# ATSAM3X8H device description
Architecture: CORTEX-M3; Family: SAM3; Series: SAM3XA
Registers are 32-bit, read-write, no defined reset value unless marked. A register's access mark holds for its fields unless they carry their own. Offsets are from the block's base; [hi:lo] are bit positions; {n}, {i} and the like mark numbered series.

## TRNG — True Random Number Generator
Instances: TRNG 0x400BC000
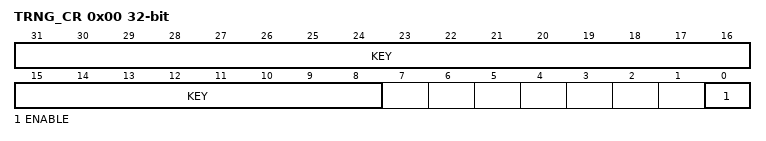
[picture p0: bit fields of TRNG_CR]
0x00 TRNG_CR wo — Control Register
  [31:8] KEY — Security Key
  [0] ENABLE — Enables the TRNG to provide random values
0x10 TRNG_IER wo — Interrupt Enable Register
  [0] DATRDY — Data Ready Interrupt Enable
0x14 TRNG_IDR wo — Interrupt Disable Register
  [0] DATRDY — Data Ready Interrupt Disable
0x18 TRNG_IMR ro — Interrupt Mask Register
  [0] DATRDY — Data Ready Interrupt Mask
0x1C TRNG_ISR ro — Interrupt Status Register
  [0] DATRDY — Data Ready
0x50 TRNG_ODATA ro — Output Data Register
  [31:0] ODATA — Output Data

## UART — Universal Asynchronous Receiver Transmitter
Instances: UART 0x400E0800
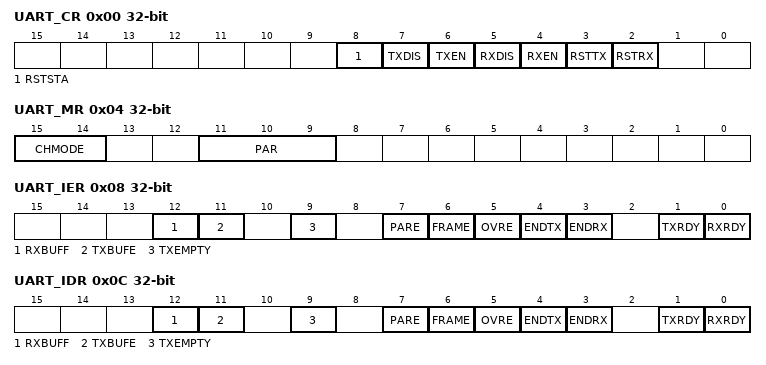
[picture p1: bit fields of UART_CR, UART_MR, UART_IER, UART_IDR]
0x00 UART_CR wo — Control Register
  [8] RSTSTA — Reset Status Bits
  [7] TXDIS — Transmitter Disable
  [6] TXEN — Transmitter Enable
  [5] RXDIS — Receiver Disable
  [4] RXEN — Receiver Enable
  [3] RSTTX — Reset Transmitter
  [2] RSTRX — Reset Receiver
0x04 UART_MR — Mode Register
  [15:14] CHMODE — Channel Mode
    0=NORMAL (Normal Mode); 1=AUTOMATIC (Automatic Echo); 2=LOCAL_LOOPBACK; 3=REMOTE_LOOPBACK
  [11:9] PAR — Parity Type
    0=EVEN (Even Parity); 1=ODD (Odd Parity); 2=SPACE (Space: parity forced to 0); 3=MARK (Mark: parity forced to 1); 4=NO (No Parity)
0x08 UART_IER wo — Interrupt Enable Register
  [12] RXBUFF — Enable Buffer Full Interrupt
  [11] TXBUFE — Enable Buffer Empty Interrupt
  [9] TXEMPTY — Enable TXEMPTY Interrupt
  [7] PARE — Enable Parity Error Interrupt
  [6] FRAME — Enable Framing Error Interrupt
  [5] OVRE — Enable Overrun Error Interrupt
  [4] ENDTX — Enable End of Transmit Interrupt
  [3] ENDRX — Enable End of Receive Transfer Interrupt
  [1] TXRDY — Enable TXRDY Interrupt
  [0] RXRDY — Enable RXRDY Interrupt
0x0C UART_IDR wo — Interrupt Disable Register
  [12] RXBUFF — Disable Buffer Full Interrupt
  [11] TXBUFE — Disable Buffer Empty Interrupt
  [9] TXEMPTY — Disable TXEMPTY Interrupt
  [7] PARE — Disable Parity Error Interrupt
  [6] FRAME — Disable Framing Error Interrupt
  [5] OVRE — Disable Overrun Error Interrupt
  [4] ENDTX — Disable End of Transmit Interrupt
  [3] ENDRX — Disable End of Receive Transfer Interrupt
  [1] TXRDY — Disable TXRDY Interrupt
  [0] RXRDY — Disable RXRDY Interrupt
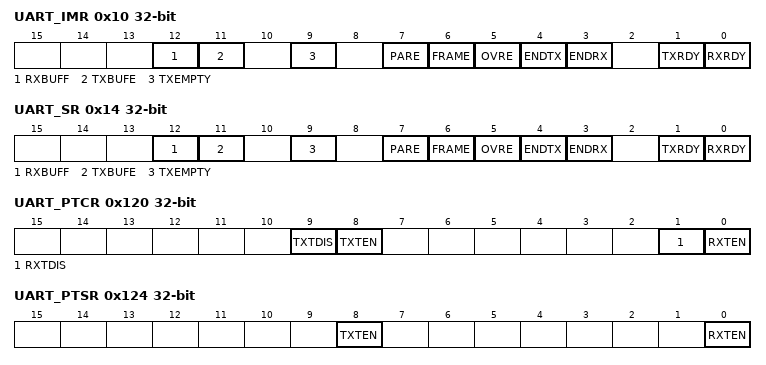
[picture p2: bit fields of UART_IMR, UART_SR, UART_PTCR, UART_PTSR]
0x10 UART_IMR ro — Interrupt Mask Register
  [12] RXBUFF — Mask RXBUFF Interrupt
  [11] TXBUFE — Mask TXBUFE Interrupt
  [9] TXEMPTY — Mask TXEMPTY Interrupt
  [7] PARE — Mask Parity Error Interrupt
  [6] FRAME — Mask Framing Error Interrupt
  [5] OVRE — Mask Overrun Error Interrupt
  [4] ENDTX — Mask End of Transmit Interrupt
  [3] ENDRX — Mask End of Receive Transfer Interrupt
  [1] TXRDY — Disable TXRDY Interrupt
  [0] RXRDY — Mask RXRDY Interrupt
0x14 UART_SR ro — Status Register
  [12] RXBUFF — Receive Buffer Full
  [11] TXBUFE — Transmission Buffer Empty
  [9] TXEMPTY — Transmitter Empty
  [7] PARE — Parity Error
  [6] FRAME — Framing Error
  [5] OVRE — Overrun Error
  [4] ENDTX — End of Transmitter Transfer
  [3] ENDRX — End of Receiver Transfer
  [1] TXRDY — Transmitter Ready
  [0] RXRDY — Receiver Ready
0x18 UART_RHR ro — Receive Holding Register
  [7:0] RXCHR — Received Character
0x1C UART_THR wo — Transmit Holding Register
  [7:0] TXCHR — Character to be Transmitted
0x20 UART_BRGR — Baud Rate Generator Register
  [15:0] CD — Clock Divisor
0x100 UART_RPR — Receive Pointer Register
  [31:0] RXPTR
0x104 UART_RCR — Receive Counter Register
  [15:0] RXCTR
0x108 UART_TPR — Transmit Pointer Register
  [31:0] TXPTR — Transmit Counter Register
0x10C UART_TCR — Transmit Counter Register
  [15:0] TXCTR
0x110 UART_RNPR — Receive Next Pointer Register
  [31:0] RXNPTR — Receive Next Pointer
0x114 UART_RNCR — Receive Next Counter Register
  [15:0] RXNCTR — Receive Next Counter
0x118 UART_TNPR — Transmit Next Pointer Register
  [31:0] TXNPTR — Transmit Next Pointer
0x11C UART_TNCR — Transmit Next Counter Register
  [15:0] TXNCTR — Transmit Counter Next
0x120 UART_PTCR wo — Transfer Control Register
  [9] TXTDIS — Transmitter Transfer Disable
  [8] TXTEN — Transmitter Transfer Enable
  [1] RXTDIS — Receiver Transfer Disable
  [0] RXTEN — Receiver Transfer Enable
0x124 UART_PTSR ro — Transfer Status Register
  [8] TXTEN — Transmitter Transfer Enable
  [0] RXTEN — Receiver Transfer Enable

## WDT — Watchdog Timer
Instances: WDT 0x400E1A50
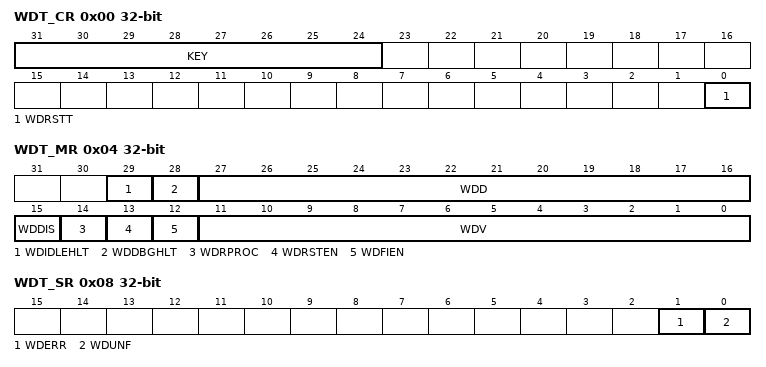
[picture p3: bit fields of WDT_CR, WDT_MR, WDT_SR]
0x00 WDT_CR wo — Control Register
  [31:24] KEY — Password.
    165=PASSWD (Writing any other value in this field aborts the write operation.)
  [0] WDRSTT — Watchdog Restart
0x04 WDT_MR — Mode Register
  [29] WDIDLEHLT — Watchdog Idle Halt
  [28] WDDBGHLT — Watchdog Debug Halt
  [27:16] WDD — Watchdog Delta Value
  [15] WDDIS — Watchdog Disable
  [14] WDRPROC — Watchdog Reset Processor
  [13] WDRSTEN — Watchdog Reset Enable
  [12] WDFIEN — Watchdog Fault Interrupt Enable
  [11:0] WDV — Watchdog Counter Value
0x08 WDT_SR ro — Status Register
  [1] WDERR — Watchdog Error
  [0] WDUNF — Watchdog Underflow

## GPNVMBITS (FUSES module)
Instances: GPNVMBITS 0 in fuses
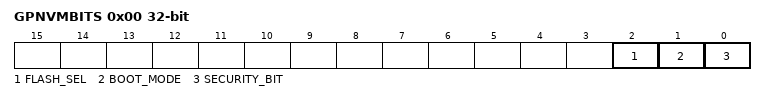
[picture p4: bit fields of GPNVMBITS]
0x00 GPNVMBITS
  [2] FLASH_SEL — Flash bank selector
    0=BANK_0 (Boot from Bank 0); 1=BANK_1 (Boot from Bank 1)
  [1] BOOT_MODE — Boot Mode Selection
    0=ROM (Boot from ROM); 1=FLASH (Boot from flash)
  [0] SECURITY_BIT ro

## LOCKBIT
Instances: LOCKBIT 0 in lockbits
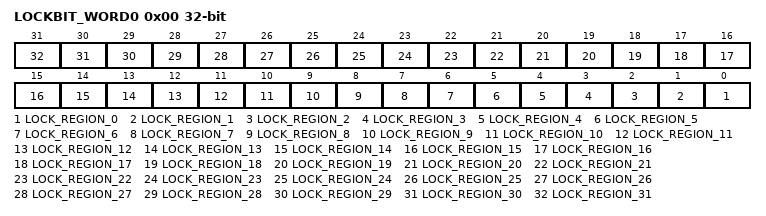
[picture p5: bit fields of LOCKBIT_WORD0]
0x00 LOCKBIT_WORD0 — Lock Bits Word 0
  [n] LOCK_REGION_{n} (n=0..31)

## SysTick — System timer
Instances: SysTick 0xE000E010
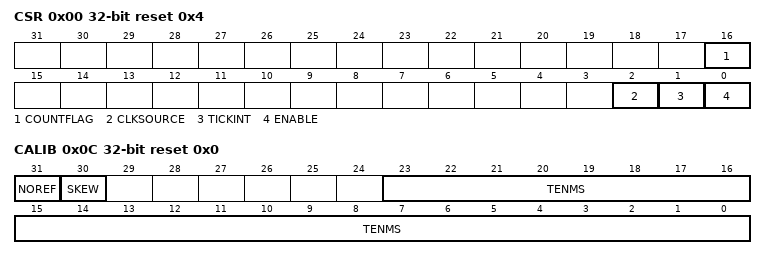
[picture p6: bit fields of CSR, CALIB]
0x00 CSR access not given reset 0x4 — SysTick Control and Status Register
  [16] COUNTFLAG
  [2] CLKSOURCE
    0=external clock; 1=processor clock
  [1] TICKINT
    0=counting down to 0 does not assert the SysTick exception request; 1=counting down to 0 asserts the SysTick exception request
  [0] ENABLE
    0=counter disabled; 1=counter enabled
0x04 RVR access not given reset 0x0 — SysTick Reload Value Register
  [23:0] RELOAD — Value to load into the SysTick Current Value Register when the counter reaches 0
0x08 CVR access not given reset 0x0 — SysTick Current Value Register
  [23:0] CURRENT — Current value at the time the register is accessed
0x0C CALIB access not given reset 0x0 — SysTick Calibration Value Register
  [31] NOREF
    0=The reference clock is provided; 1=The reference clock is not provided
  [30] SKEW
    0=10ms calibration value is exact; 1=10ms calibration value is inexact, because of the clock frequency
  [23:0] TENMS — Reload value to use for 10ms timing

## NVIC — Nested Vectored Interrupt Controller
Instances: NVIC 0xE000E100
{0x0+4i} NVICISER{i} access not given reset 0x0 (i=0..3) — Interrupt Set Enable Register n
  [31:0] SETENA — Interrupt set enable bits
{0x80+4i} NVICICER{i} access not given reset 0x0 (i=0..3) — Interrupt Clear Enable Register n
  [31:0] CLRENA — Interrupt clear-enable bits
{0x100+4i} NVICISPR{i} access not given reset 0x0 (i=0..3) — Interrupt Set Pending Register n
  [31:0] SETPEND — Interrupt set-pending bits
{0x180+4i} NVICICPR{i} access not given reset 0x0 (i=0..3) — Interrupt Clear Pending Register n
  [31:0] CLRPEND — Interrupt clear-pending bits
{0x200+4i} NVICIABR{i} access not given reset 0x0 (i=0..3) — Interrupt Active bit Register n
  [31:0] ACTIVE — Interrupt active flags
{0x300+i} NVICIP{i} 8-bit access not given reset 0x0 (i=0..105) — Interrupt Priority Register n
  [7:0] PRI{i} — Priority of interrupt {i}
0xE00 NVICSTIR access not given reset 0x0 — Software Trigger Interrupt Register
  [8:0] INTID — Interrupt ID of the interrupt to trigger, in the range 0-239. For example, a value of 0x03 specifies interrupt IRQ3.
